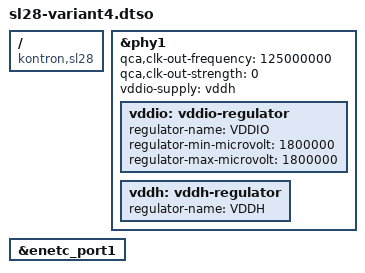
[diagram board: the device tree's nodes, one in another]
/*
 * Device Tree Include file for Kontron SMARC-sAL28.
 */

/dts-v1/;
/plugin/;

/ {
	compatible = "kontron,sl28", "fsl,ls1028a";

	fragment@0 {
		target = <&phy1>;
		__overlay__ {
			qca,clk-out-frequency = <125000000>;
			qca,clk-out-strength = <0>;
			vddio-supply = <&vddh>;
			status = "okay";

			vddio: vddio-regulator {
				regulator-name = "VDDIO";
				regulator-min-microvolt = <1800000>;
				regulator-max-microvolt = <1800000>;
			};

			vddh: vddh-regulator {
				regulator-name = "VDDH";
			};
		};
	};

	fragment@1 {
		target = <&enetc_port1>;
		__overlay__ {
			status = "okay";
		};
	};
};
